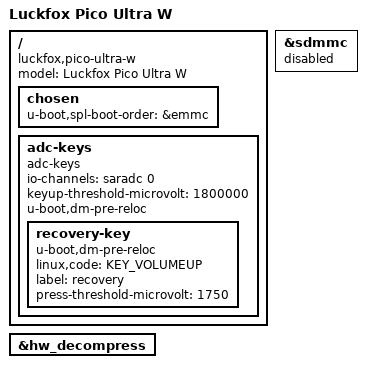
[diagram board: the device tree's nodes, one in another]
// SPDX-License-Identifier: (GPL-2.0+ OR MIT)
/*
 * Luckfox Pico Ultra W (Rockchip RV1106G3, 8GB eMMC)
 *
 * Based on rv1106-evb.dts from rockchip-linux/u-boot next-dev.
 */

/dts-v1/;

#include "rv1106.dtsi"
#include "rv1106-u-boot.dtsi"
#include <dt-bindings/input/input.h>

/ {
	model = "Luckfox Pico Ultra W";
	compatible = "luckfox,pico-ultra-w", "rockchip,rv1106";

	chosen {
		/* eMMC is the only boot medium on this board */
		u-boot,spl-boot-order = &emmc;
	};

	/*
	 * RECOVERY key on SARADC_IN0 (GPIO4_C0), pulled up to VCCIO2 (1.8V).
	 * Rockchip U-Boot uses KEY_VOLUMEUP to enter download mode.
	 */
	adc-keys {
		compatible = "adc-keys";
		io-channels = <&saradc 0>;
		io-channel-names = "buttons";
		keyup-threshold-microvolt = <1800000>;
		u-boot,dm-pre-reloc;
		status = "okay";

		recovery-key {
			u-boot,dm-pre-reloc;
			linux,code = <KEY_VOLUMEUP>;
			label = "recovery";
			press-threshold-microvolt = <1750>;
		};
	};
};

&hw_decompress {
	u-boot,dm-spl;
	status = "okay";
};

/* SDMMC is wired to the SDIO Wi-Fi module, there is no SD card slot */
&sdmmc {
	status = "disabled";
};
